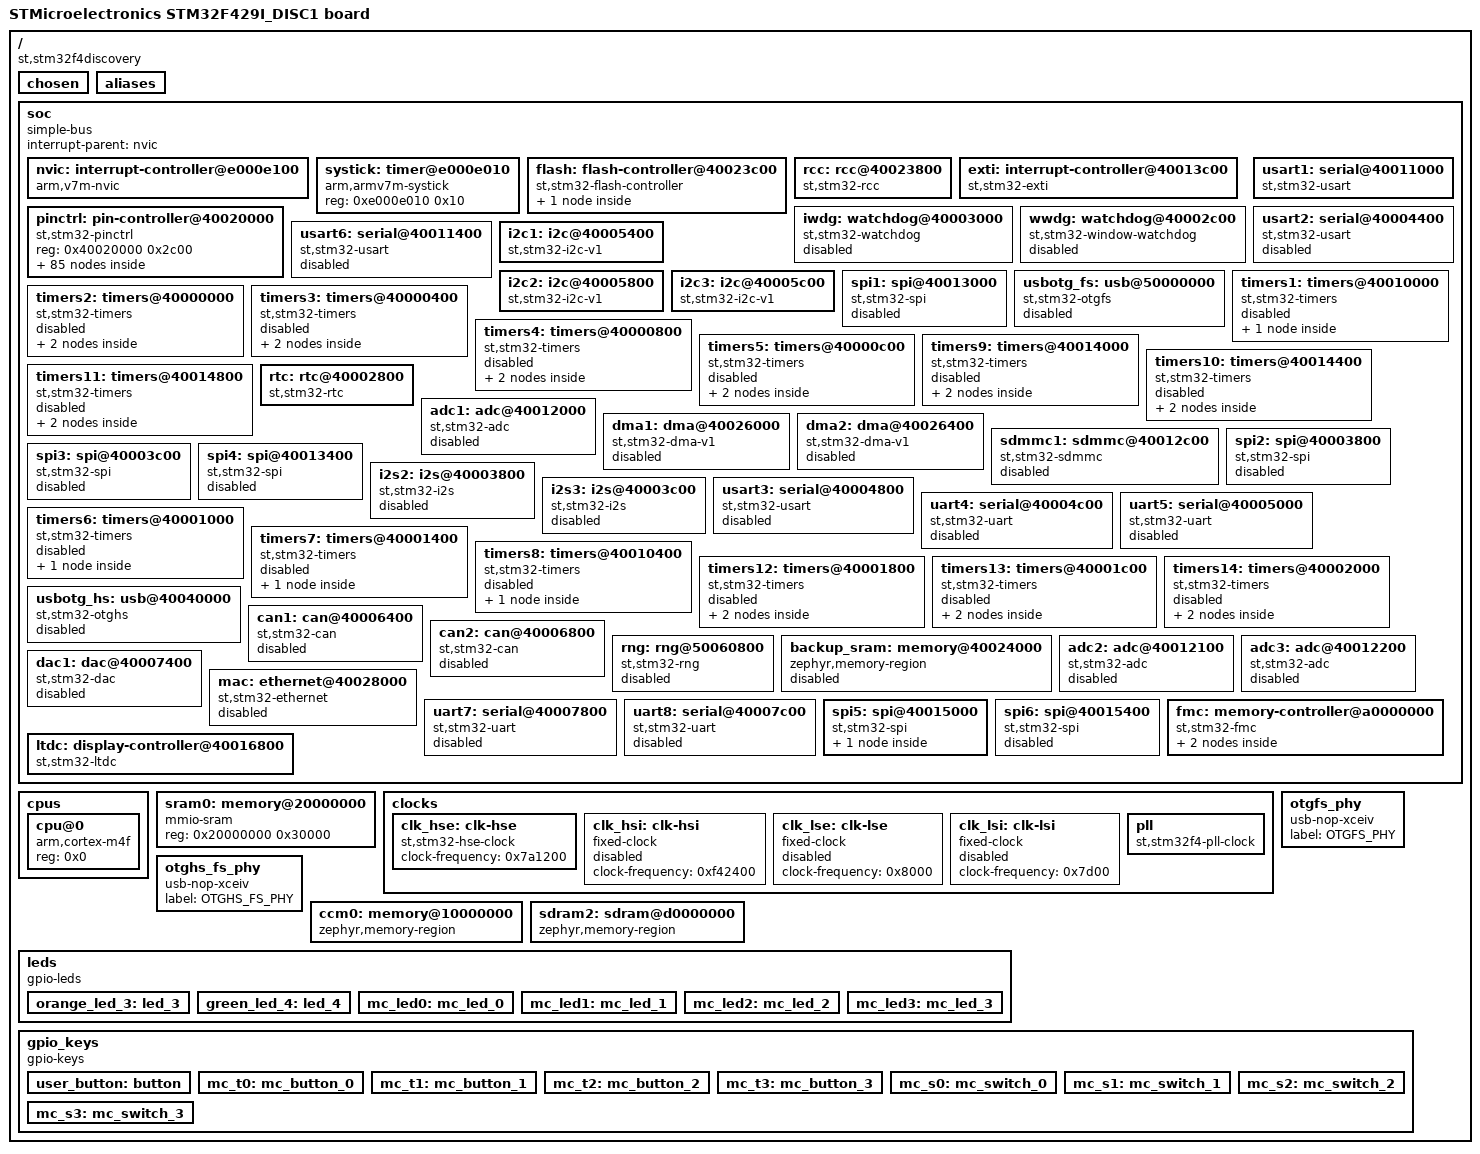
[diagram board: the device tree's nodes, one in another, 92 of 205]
/dts-v1/;

/ {
	#address-cells = < 0x1 >;
	#size-cells = < 0x1 >;
	model = "STMicroelectronics STM32F429I_DISC1 board";
	compatible = "st,stm32f4discovery";
	chosen {
		zephyr,flash-controller = &flash;
		zephyr,entropy = &rng;
		zephyr,console = &usart1;
		zephyr,shell-uart = &usart1;
		zephyr,sram = &sram0;
		zephyr,flash = &flash0;
		zephyr,ccm = &ccm0;
		zephyr,display = &ili9341;
		zephyr,tracing-uart = &usart1;
	};
	aliases {
		led0 = &green_led_4;
		sw0 = &user_button;
	};
	soc {
		#address-cells = < 0x1 >;
		#size-cells = < 0x1 >;
		compatible = "simple-bus";
		interrupt-parent = < &nvic >;
		ranges;
		nvic: interrupt-controller@e000e100 {
			#address-cells = < 0x1 >;
			compatible = "arm,v7m-nvic";
			reg = < 0xe000e100 0xc00 >;
			interrupt-controller;
			#interrupt-cells = < 0x2 >;
			arm,num-irq-priority-bits = < 0x4 >;
			phandle = < 0x1 >;
		};
		systick: timer@e000e010 {
			compatible = "arm,armv7m-systick";
			reg = < 0xe000e010 0x10 >;
		};
		flash: flash-controller@40023c00 {
			compatible = "st,stm32-flash-controller", "st,stm32f4-flash-controller";
			label = "FLASH_CTRL";
			reg = < 0x40023c00 0x400 >;
			interrupts = < 0x4 0x0 >;
			#address-cells = < 0x1 >;
			#size-cells = < 0x1 >;
			flash0: flash@8000000 {
				compatible = "st,stm32-nv-flash", "soc-nv-flash";
				label = "FLASH_STM32";
				write-block-size = < 0x1 >;
				max-erase-time = < 0xfa0 >;
				reg = < 0x8000000 0x200000 >;
			};
		};
		rcc: rcc@40023800 {
			compatible = "st,stm32-rcc";
			#clock-cells = < 0x2 >;
			reg = < 0x40023800 0x400 >;
			clocks = < &pll >;
			clock-frequency = < 0xa037a00 >;
			ahb-prescaler = < 0x1 >;
			apb1-prescaler = < 0x4 >;
			apb2-prescaler = < 0x2 >;
			phandle = < 0x3 >;
		};
		exti: interrupt-controller@40013c00 {
			compatible = "st,stm32-exti";
			interrupt-controller;
			#interrupt-cells = < 0x1 >;
			reg = < 0x40013c00 0x400 >;
		};
		pinctrl: pin-controller@40020000 {
			compatible = "st,stm32-pinctrl";
			#address-cells = < 0x1 >;
			#size-cells = < 0x1 >;
			reg = < 0x40020000 0x2c00 >;
			gpioa: gpio@40020000 {
				compatible = "st,stm32-gpio";
				gpio-controller;
				#gpio-cells = < 0x2 >;
				reg = < 0x40020000 0x400 >;
				clocks = < &rcc 0x30 0x1 >;
				label = "GPIOA";
				phandle = < 0x57 >;
			};
			gpiob: gpio@40020400 {
				compatible = "st,stm32-gpio";
				gpio-controller;
				#gpio-cells = < 0x2 >;
				reg = < 0x40020400 0x400 >;
				clocks = < &rcc 0x30 0x2 >;
				label = "GPIOB";
			};
			gpioc: gpio@40020800 {
				compatible = "st,stm32-gpio";
				gpio-controller;
				#gpio-cells = < 0x2 >;
				reg = < 0x40020800 0x400 >;
				clocks = < &rcc 0x30 0x4 >;
				label = "GPIOC";
				phandle = < 0x13 >;
			};
			gpiod: gpio@40020c00 {
				compatible = "st,stm32-gpio";
				gpio-controller;
				#gpio-cells = < 0x2 >;
				reg = < 0x40020c00 0x400 >;
				clocks = < &rcc 0x30 0x8 >;
				label = "GPIOD";
				phandle = < 0x14 >;
			};
			gpioe: gpio@40021000 {
				compatible = "st,stm32-gpio";
				gpio-controller;
				#gpio-cells = < 0x2 >;
				reg = < 0x40021000 0x400 >;
				clocks = < &rcc 0x30 0x10 >;
				label = "GPIOE";
				phandle = < 0x56 >;
			};
			gpiof: gpio@40021400 {
				compatible = "st,stm32-gpio";
				gpio-controller;
				#gpio-cells = < 0x2 >;
				reg = < 0x40021400 0x400 >;
				clocks = < &rcc 0x30 0x20 >;
				label = "GPIOF";
				phandle = < 0x58 >;
			};
			gpiog: gpio@40021800 {
				compatible = "st,stm32-gpio";
				gpio-controller;
				#gpio-cells = < 0x2 >;
				reg = < 0x40021800 0x400 >;
				clocks = < &rcc 0x30 0x40 >;
				label = "GPIOG";
				phandle = < 0x55 >;
			};
			gpioh: gpio@40021c00 {
				compatible = "st,stm32-gpio";
				gpio-controller;
				#gpio-cells = < 0x2 >;
				reg = < 0x40021c00 0x400 >;
				clocks = < &rcc 0x30 0x80 >;
				label = "GPIOH";
			};
			gpioi: gpio@40022000 {
				compatible = "st,stm32-gpio";
				gpio-controller;
				#gpio-cells = < 0x2 >;
				reg = < 0x40022000 0x400 >;
				clocks = < &rcc 0x30 0x100 >;
				label = "GPIOI";
			};
			gpioj: gpio@40022400 {
				compatible = "st,stm32-gpio";
				gpio-controller;
				#gpio-cells = < 0x2 >;
				reg = < 0x40022400 0x400 >;
				clocks = < &rcc 0x30 0x200 >;
				label = "GPIOJ";
			};
			gpiok: gpio@40022800 {
				compatible = "st,stm32-gpio";
				gpio-controller;
				#gpio-cells = < 0x2 >;
				reg = < 0x40022800 0x400 >;
				clocks = < &rcc 0x30 0x400 >;
				label = "GPIOK";
			};
			fmc_sdcke1_pb5: fmc_sdcke1_pb5 {
				pinmux = < 0x2ac >;
				bias-pull-up;
				slew-rate = "very-high-speed";
				phandle = < 0x19 >;
			};
			fmc_sdne1_pb6: fmc_sdne1_pb6 {
				pinmux = < 0x2cc >;
				bias-pull-up;
				slew-rate = "very-high-speed";
				phandle = < 0x1a >;
			};
			fmc_sdnwe_pc0: fmc_sdnwe_pc0 {
				pinmux = < 0x40c >;
				bias-pull-up;
				slew-rate = "very-high-speed";
				phandle = < 0x18 >;
			};
			fmc_d2_pd0: fmc_d2_pd0 {
				pinmux = < 0x60c >;
				bias-pull-up;
				slew-rate = "very-high-speed";
				phandle = < 0x2f >;
			};
			fmc_d3_pd1: fmc_d3_pd1 {
				pinmux = < 0x62c >;
				bias-pull-up;
				slew-rate = "very-high-speed";
				phandle = < 0x30 >;
			};
			fmc_d13_pd8: fmc_d13_pd8 {
				pinmux = < 0x70c >;
				bias-pull-up;
				slew-rate = "very-high-speed";
				phandle = < 0x3a >;
			};
			fmc_d14_pd9: fmc_d14_pd9 {
				pinmux = < 0x72c >;
				bias-pull-up;
				slew-rate = "very-high-speed";
				phandle = < 0x3b >;
			};
			fmc_d15_pd10: fmc_d15_pd10 {
				pinmux = < 0x74c >;
				bias-pull-up;
				slew-rate = "very-high-speed";
				phandle = < 0x3c >;
			};
			fmc_d0_pd14: fmc_d0_pd14 {
				pinmux = < 0x7cc >;
				bias-pull-up;
				slew-rate = "very-high-speed";
				phandle = < 0x2d >;
			};
			fmc_d1_pd15: fmc_d1_pd15 {
				pinmux = < 0x7ec >;
				bias-pull-up;
				slew-rate = "very-high-speed";
				phandle = < 0x2e >;
			};
			fmc_nbl0_pe0: fmc_nbl0_pe0 {
				pinmux = < 0x80c >;
				bias-pull-up;
				slew-rate = "very-high-speed";
				phandle = < 0x15 >;
			};
			fmc_nbl1_pe1: fmc_nbl1_pe1 {
				pinmux = < 0x82c >;
				bias-pull-up;
				slew-rate = "very-high-speed";
				phandle = < 0x16 >;
			};
			fmc_d4_pe7: fmc_d4_pe7 {
				pinmux = < 0x8ec >;
				bias-pull-up;
				slew-rate = "very-high-speed";
				phandle = < 0x31 >;
			};
			fmc_d5_pe8: fmc_d5_pe8 {
				pinmux = < 0x90c >;
				bias-pull-up;
				slew-rate = "very-high-speed";
				phandle = < 0x32 >;
			};
			fmc_d6_pe9: fmc_d6_pe9 {
				pinmux = < 0x92c >;
				bias-pull-up;
				slew-rate = "very-high-speed";
				phandle = < 0x33 >;
			};
			fmc_d7_pe10: fmc_d7_pe10 {
				pinmux = < 0x94c >;
				bias-pull-up;
				slew-rate = "very-high-speed";
				phandle = < 0x34 >;
			};
			fmc_d8_pe11: fmc_d8_pe11 {
				pinmux = < 0x96c >;
				bias-pull-up;
				slew-rate = "very-high-speed";
				phandle = < 0x35 >;
			};
			fmc_d9_pe12: fmc_d9_pe12 {
				pinmux = < 0x98c >;
				bias-pull-up;
				slew-rate = "very-high-speed";
				phandle = < 0x36 >;
			};
			fmc_d10_pe13: fmc_d10_pe13 {
				pinmux = < 0x9ac >;
				bias-pull-up;
				slew-rate = "very-high-speed";
				phandle = < 0x37 >;
			};
			fmc_d11_pe14: fmc_d11_pe14 {
				pinmux = < 0x9cc >;
				bias-pull-up;
				slew-rate = "very-high-speed";
				phandle = < 0x38 >;
			};
			fmc_d12_pe15: fmc_d12_pe15 {
				pinmux = < 0x9ec >;
				bias-pull-up;
				slew-rate = "very-high-speed";
				phandle = < 0x39 >;
			};
			fmc_a0_pf0: fmc_a0_pf0 {
				pinmux = < 0xa0c >;
				bias-pull-up;
				slew-rate = "very-high-speed";
				phandle = < 0x1d >;
			};
			fmc_a1_pf1: fmc_a1_pf1 {
				pinmux = < 0xa2c >;
				bias-pull-up;
				slew-rate = "very-high-speed";
				phandle = < 0x1e >;
			};
			fmc_a2_pf2: fmc_a2_pf2 {
				pinmux = < 0xa4c >;
				bias-pull-up;
				slew-rate = "very-high-speed";
				phandle = < 0x1f >;
			};
			fmc_a3_pf3: fmc_a3_pf3 {
				pinmux = < 0xa6c >;
				bias-pull-up;
				slew-rate = "very-high-speed";
				phandle = < 0x20 >;
			};
			fmc_a4_pf4: fmc_a4_pf4 {
				pinmux = < 0xa8c >;
				bias-pull-up;
				slew-rate = "very-high-speed";
				phandle = < 0x21 >;
			};
			fmc_a5_pf5: fmc_a5_pf5 {
				pinmux = < 0xaac >;
				bias-pull-up;
				slew-rate = "very-high-speed";
				phandle = < 0x22 >;
			};
			fmc_sdnras_pf11: fmc_sdnras_pf11 {
				pinmux = < 0xb6c >;
				bias-pull-up;
				slew-rate = "very-high-speed";
				phandle = < 0x1b >;
			};
			fmc_a6_pf12: fmc_a6_pf12 {
				pinmux = < 0xb8c >;
				bias-pull-up;
				slew-rate = "very-high-speed";
				phandle = < 0x23 >;
			};
			fmc_a7_pf13: fmc_a7_pf13 {
				pinmux = < 0xbac >;
				bias-pull-up;
				slew-rate = "very-high-speed";
				phandle = < 0x24 >;
			};
			fmc_a8_pf14: fmc_a8_pf14 {
				pinmux = < 0xbcc >;
				bias-pull-up;
				slew-rate = "very-high-speed";
				phandle = < 0x25 >;
			};
			fmc_a9_pf15: fmc_a9_pf15 {
				pinmux = < 0xbec >;
				bias-pull-up;
				slew-rate = "very-high-speed";
				phandle = < 0x26 >;
			};
			fmc_a10_pg0: fmc_a10_pg0 {
				pinmux = < 0xc0c >;
				bias-pull-up;
				slew-rate = "very-high-speed";
				phandle = < 0x27 >;
			};
			fmc_a11_pg1: fmc_a11_pg1 {
				pinmux = < 0xc2c >;
				bias-pull-up;
				slew-rate = "very-high-speed";
				phandle = < 0x28 >;
			};
			fmc_a12_pg2: fmc_a12_pg2 {
				pinmux = < 0xc4c >;
				bias-pull-up;
				slew-rate = "very-high-speed";
				phandle = < 0x29 >;
			};
			fmc_a13_pg3: fmc_a13_pg3 {
				pinmux = < 0xc6c >;
				bias-pull-up;
				slew-rate = "very-high-speed";
				phandle = < 0x2a >;
			};
			fmc_a14_pg4: fmc_a14_pg4 {
				pinmux = < 0xc8c >;
				bias-pull-up;
				slew-rate = "very-high-speed";
				phandle = < 0x2b >;
			};
			fmc_a15_pg5: fmc_a15_pg5 {
				pinmux = < 0xcac >;
				bias-pull-up;
				slew-rate = "very-high-speed";
				phandle = < 0x2c >;
			};
			fmc_sdclk_pg8: fmc_sdclk_pg8 {
				pinmux = < 0xd0c >;
				bias-pull-up;
				slew-rate = "very-high-speed";
				phandle = < 0x17 >;
			};
			fmc_sdncas_pg15: fmc_sdncas_pg15 {
				pinmux = < 0xdec >;
				bias-pull-up;
				slew-rate = "very-high-speed";
				phandle = < 0x1c >;
			};
			i2c1_scl_pb8: i2c1_scl_pb8 {
				pinmux = < 0x304 >;
				bias-pull-up;
				drive-open-drain;
				phandle = < 0x6 >;
			};
			i2c2_scl_pb10: i2c2_scl_pb10 {
				pinmux = < 0x344 >;
				bias-pull-up;
				drive-open-drain;
				phandle = < 0x8 >;
			};
			i2c3_scl_pa8: i2c3_scl_pa8 {
				pinmux = < 0x104 >;
				bias-pull-up;
				drive-open-drain;
				phandle = < 0xa >;
			};
			i2c1_sda_pb9: i2c1_sda_pb9 {
				pinmux = < 0x324 >;
				bias-pull-up;
				drive-open-drain;
				phandle = < 0x7 >;
			};
			i2c2_sda_pb11: i2c2_sda_pb11 {
				pinmux = < 0x364 >;
				bias-pull-up;
				drive-open-drain;
				phandle = < 0x9 >;
			};
			i2c3_sda_pc9: i2c3_sda_pc9 {
				pinmux = < 0x524 >;
				bias-pull-up;
				drive-open-drain;
				phandle = < 0xb >;
			};
			ltdc_b5_pa3: ltdc_b5_pa3 {
				pinmux = < 0x6e >;
				phandle = < 0x4c >;
			};
			ltdc_vsync_pa4: ltdc_vsync_pa4 {
				pinmux = < 0x8e >;
				phandle = < 0x52 >;
			};
			ltdc_g2_pa6: ltdc_g2_pa6 {
				pinmux = < 0xce >;
				phandle = < 0x43 >;
			};
			ltdc_r4_pa11: ltdc_r4_pa11 {
				pinmux = < 0x16e >;
				phandle = < 0x3f >;
			};
			ltdc_r5_pa12: ltdc_r5_pa12 {
				pinmux = < 0x18e >;
				phandle = < 0x40 >;
			};
			ltdc_r3_pb0: ltdc_r3_pb0 {
				pinmux = < 0x209 >;
				phandle = < 0x3e >;
			};
			ltdc_r6_pb1: ltdc_r6_pb1 {
				pinmux = < 0x229 >;
				phandle = < 0x41 >;
			};
			ltdc_b6_pb8: ltdc_b6_pb8 {
				pinmux = < 0x30e >;
				phandle = < 0x4d >;
			};
			ltdc_b7_pb9: ltdc_b7_pb9 {
				pinmux = < 0x32e >;
				phandle = < 0x4e >;
			};
			ltdc_g4_pb10: ltdc_g4_pb10 {
				pinmux = < 0x34e >;
				phandle = < 0x45 >;
			};
			ltdc_g5_pb11: ltdc_g5_pb11 {
				pinmux = < 0x36e >;
				phandle = < 0x46 >;
			};
			ltdc_hsync_pc6: ltdc_hsync_pc6 {
				pinmux = < 0x4ce >;
				phandle = < 0x51 >;
			};
			ltdc_g6_pc7: ltdc_g6_pc7 {
				pinmux = < 0x4ee >;
				phandle = < 0x47 >;
			};
			ltdc_r2_pc10: ltdc_r2_pc10 {
				pinmux = < 0x54e >;
				phandle = < 0x3d >;
			};
			ltdc_g7_pd3: ltdc_g7_pd3 {
				pinmux = < 0x66e >;
				phandle = < 0x48 >;
			};
			ltdc_b2_pd6: ltdc_b2_pd6 {
				pinmux = < 0x6ce >;
				phandle = < 0x49 >;
			};
			ltdc_de_pf10: ltdc_de_pf10 {
				pinmux = < 0xb4e >;
				phandle = < 0x4f >;
			};
			ltdc_r7_pg6: ltdc_r7_pg6 {
				pinmux = < 0xcce >;
				phandle = < 0x42 >;
			};
			ltdc_clk_pg7: ltdc_clk_pg7 {
				pinmux = < 0xcee >;
				phandle = < 0x50 >;
			};
			ltdc_g3_pg10: ltdc_g3_pg10 {
				pinmux = < 0xd49 >;
				phandle = < 0x44 >;
			};
			ltdc_b3_pg11: ltdc_b3_pg11 {
				pinmux = < 0xd6e >;
				phandle = < 0x4a >;
			};
			ltdc_b4_pg12: ltdc_b4_pg12 {
				pinmux = < 0xd89 >;
				phandle = < 0x4b >;
			};
			spi5_miso_pf8: spi5_miso_pf8 {
				pinmux = < 0xb05 >;
				bias-pull-down;
				phandle = < 0x11 >;
			};
			spi5_mosi_pf9: spi5_mosi_pf9 {
				pinmux = < 0xb25 >;
				bias-pull-down;
				phandle = < 0x12 >;
			};
			spi5_nss_pf6: spi5_nss_pf6 {
				pinmux = < 0xac5 >;
				bias-pull-up;
				phandle = < 0xf >;
			};
			spi5_sck_pf7: spi5_sck_pf7 {
				pinmux = < 0xae5 >;
				bias-pull-down;
				slew-rate = "very-high-speed";
				phandle = < 0x10 >;
			};
			usart1_rx_pa10: usart1_rx_pa10 {
				pinmux = < 0x147 >;
				phandle = < 0x5 >;
			};
			usart1_tx_pa9: usart1_tx_pa9 {
				pinmux = < 0x127 >;
				bias-pull-up;
				phandle = < 0x4 >;
			};
		};
		iwdg: watchdog@40003000 {
			compatible = "st,stm32-watchdog";
			reg = < 0x40003000 0x400 >;
			label = "IWDG";
			status = "disabled";
		};
		wwdg: watchdog@40002c00 {
			compatible = "st,stm32-window-watchdog";
			reg = < 0x40002c00 0x400 >;
			clocks = < &rcc 0x40 0x800 >;
			label = "WWDG";
			interrupts = < 0x0 0x7 >;
			status = "disabled";
		};
		usart1: serial@40011000 {
			compatible = "st,stm32-usart", "st,stm32-uart";
			reg = < 0x40011000 0x400 >;
			clocks = < &rcc 0x44 0x10 >;
			interrupts = < 0x25 0x0 >;
			status = "okay";
			label = "UART_1";
			pinctrl-0 = < &usart1_tx_pa9 &usart1_rx_pa10 >;
			pinctrl-names = "default";
			current-speed = < 0x1c200 >;
		};
		usart2: serial@40004400 {
			compatible = "st,stm32-usart", "st,stm32-uart";
			reg = < 0x40004400 0x400 >;
			clocks = < &rcc 0x40 0x20000 >;
			interrupts = < 0x26 0x0 >;
			status = "disabled";
			label = "UART_2";
		};
		usart6: serial@40011400 {
			compatible = "st,stm32-usart", "st,stm32-uart";
			reg = < 0x40011400 0x400 >;
			clocks = < &rcc 0x44 0x20 >;
			interrupts = < 0x47 0x0 >;
			status = "disabled";
			label = "UART_6";
		};
		i2c1: i2c@40005400 {
			compatible = "st,stm32-i2c-v1";
			clock-frequency = < 0x61a80 >;
			#address-cells = < 0x1 >;
			#size-cells = < 0x0 >;
			reg = < 0x40005400 0x400 >;
			clocks = < &rcc 0x40 0x200000 >;
			interrupts = < 0x1f 0x0 >, < 0x20 0x0 >;
			interrupt-names = "event", "error";
			status = "okay";
			label = "I2C_1";
			pinctrl-0 = < &i2c1_scl_pb8 &i2c1_sda_pb9 >;
			pinctrl-names = "default";
		};
		i2c2: i2c@40005800 {
			compatible = "st,stm32-i2c-v1";
			clock-frequency = < 0x61a80 >;
			#address-cells = < 0x1 >;
			#size-cells = < 0x0 >;
			reg = < 0x40005800 0x400 >;
			clocks = < &rcc 0x40 0x400000 >;
			interrupts = < 0x21 0x0 >, < 0x22 0x0 >;
			interrupt-names = "event", "error";
			status = "okay";
			label = "I2C_2";
			pinctrl-0 = < &i2c2_scl_pb10 &i2c2_sda_pb11 >;
			pinctrl-names = "default";
		};
		i2c3: i2c@40005c00 {
			compatible = "st,stm32-i2c-v1";
			clock-frequency = < 0x61a80 >;
			#address-cells = < 0x1 >;
			#size-cells = < 0x0 >;
			reg = < 0x40005c00 0x400 >;
			clocks = < &rcc 0x40 0x800000 >;
			interrupts = < 0x48 0x0 >, < 0x49 0x0 >;
			interrupt-names = "event", "error";
			status = "okay";
			label = "I2C_3";
			pinctrl-0 = < &i2c3_scl_pa8 &i2c3_sda_pc9 >;
			pinctrl-names = "default";
		};
		spi1: spi@40013000 {
			compatible = "st,stm32-spi";
			#address-cells = < 0x1 >;
			#size-cells = < 0x0 >;
			reg = < 0x40013000 0x400 >;
			clocks = < &rcc 0x44 0x1000 >;
			interrupts = < 0x23 0x5 >;
			status = "disabled";
			label = "SPI_1";
		};
		usbotg_fs: usb@50000000 {
			compatible = "st,stm32-otgfs";
			reg = < 0x50000000 0x40000 >;
			interrupts = < 0x43 0x0 >;
			interrupt-names = "otgfs";
			num-bidir-endpoints = < 0x4 >;
			ram-size = < 0x500 >;
			maximum-speed = "full-speed";
			phys = < &otgfs_phy >;
			clocks = < &rcc 0x34 0x80 >;
			status = "disabled";
			label = "OTGFS";
		};
		timers1: timers@40010000 {
			compatible = "st,stm32-timers";
			reg = < 0x40010000 0x400 >;
			clocks = < &rcc 0x44 0x1 >;
			interrupts = < 0x18 0x0 >, < 0x19 0x0 >, < 0x1a 0x0 >, < 0x1b 0x0 >;
			interrupt-names = "brk", "up", "trgcom", "cc";
			st,prescaler = < 0x0 >;
			status = "disabled";
			label = "TIMERS_1";
			pwm {
				compatible = "st,stm32-pwm";
				status = "disabled";
				label = "PWM_1";
				#pwm-cells = < 0x3 >;
			};
		};
		timers2: timers@40000000 {
			compatible = "st,stm32-timers";
			reg = < 0x40000000 0x400 >;
			clocks = < &rcc 0x40 0x1 >;
			interrupts = < 0x1c 0x0 >;
			interrupt-names = "global";
			st,prescaler = < 0x0 >;
			status = "disabled";
			label = "TIMERS_2";
			pwm {
				compatible = "st,stm32-pwm";
				status = "disabled";
				label = "PWM_2";
				#pwm-cells = < 0x3 >;
			};
			counter {
				compatible = "st,stm32-counter";
				status = "disabled";
				label = "COUNTER_2";
			};
		};
		timers3: timers@40000400 {
			compatible = "st,stm32-timers";
			reg = < 0x40000400 0x400 >;
			clocks = < &rcc 0x40 0x2 >;
			interrupts = < 0x1d 0x0 >;
			interrupt-names = "global";
			st,prescaler = < 0x0 >;
			status = "disabled";
			label = "TIMERS_3";
			pwm {
				compatible = "st,stm32-pwm";
				status = "disabled";
				label = "PWM_3";
				#pwm-cells = < 0x3 >;
			};
			counter {
				compatible = "st,stm32-counter";
				status = "disabled";
				label = "COUNTER_3";
			};
		};
		timers4: timers@40000800 {
			compatible = "st,stm32-timers";
			reg = < 0x40000800 0x400 >;
			clocks = < &rcc 0x40 0x4 >;
			interrupts = < 0x1e 0x0 >;
			interrupt-names = "global";
			st,prescaler = < 0x0 >;
			status = "disabled";
			label = "TIMERS_4";
			pwm {
				compatible = "st,stm32-pwm";
				status = "disabled";
				label = "PWM_4";
				#pwm-cells = < 0x3 >;
			};
			counter {
				compatible = "st,stm32-counter";
				status = "disabled";
				label = "COUNTER_4";
			};
		};
		timers5: timers@40000c00 {
			compatible = "st,stm32-timers";
			reg = < 0x40000c00 0x400 >;
			clocks = < &rcc 0x40 0x8 >;
			interrupts = < 0x32 0x0 >;
			interrupt-names = "global";
			st,prescaler = < 0x0 >;
			status = "disabled";
			label = "TIMERS_5";
			pwm {
				compatible = "st,stm32-pwm";
				status = "disabled";
				label = "PWM_5";
				#pwm-cells = < 0x3 >;
			};
			counter {
				compatible = "st,stm32-counter";
				status = "disabled";
				label = "COUNTER_5";
			};
		};
		timers9: timers@40014000 {
			compatible = "st,stm32-timers";
			reg = < 0x40014000 0x400 >;
			clocks = < &rcc 0x44 0x10000 >;
			interrupts = < 0x18 0x0 >;
			interrupt-names = "global";
			st,prescaler = < 0x0 >;
			status = "disabled";
			label = "TIMERS_9";
			pwm {
				compatible = "st,stm32-pwm";
				status = "disabled";
				label = "PWM_9";
				#pwm-cells = < 0x3 >;
			};
			counter {
				compatible = "st,stm32-counter";
				status = "disabled";
				label = "COUNTER_9";
			};
		};
		timers10: timers@40014400 {
			compatible = "st,stm32-timers";
			reg = < 0x40014400 0x400 >;
			clocks = < &rcc 0x44 0x20000 >;
			interrupts = < 0x19 0x0 >;
			interrupt-names = "global";
			st,prescaler = < 0x0 >;
			status = "disabled";
			label = "TIMERS_10";
			pwm {
				compatible = "st,stm32-pwm";
				status = "disabled";
				label = "PWM_10";
				#pwm-cells = < 0x3 >;
			};
			counter {
				compatible = "st,stm32-counter";
				status = "disabled";
				label = "COUNTER_10";
			};
		};
		timers11: timers@40014800 {
			compatible = "st,stm32-timers";
			reg = < 0x40014800 0x400 >;
			clocks = < &rcc 0x44 0x40000 >;
			interrupts = < 0x1a 0x0 >;
			interrupt-names = "global";
			st,prescaler = < 0x0 >;
			status = "disabled";
			label = "TIMERS_11";
			pwm {
				compatible = "st,stm32-pwm";
				status = "disabled";
				label = "PWM_11";
				#pwm-cells = < 0x3 >;
			};
			counter {
				compatible = "st,stm32-counter";
				status = "disabled";
				label = "COUNTER_11";
			};
		};
		rtc: rtc@40002800 {
			compatible = "st,stm32-rtc";
			reg = < 0x40002800 0x400 >;
			interrupts = < 0x29 0x0 >;
			clocks = < &rcc 0x40 0x10000000 >;
			prescaler = < 0x8000 >;
			status = "okay";
			label = "RTC_0";
		};
		adc1: adc@40012000 {
			compatible = "st,stm32-adc";
			reg = < 0x40012000 0x400 >;
			clocks = < &rcc 0x44 0x100 >;
			interrupts = < 0x12 0x0 >;
			status = "disabled";
			label = "ADC_1";
			#io-channel-cells = < 0x1 >;
			has-temp-channel;
			has-vref-channel;
		};
		dma1: dma@40026000 {
			compatible = "st,stm32-dma-v1";
			#dma-cells = < 0x4 >;
			reg = < 0x40026000 0x400 >;
			interrupts = < 0xb 0x0 0xc 0x0 0xd 0x0 0xe 0x0 0xf 0x0 0x10 0x0 0x11 0x0 0x2f 0x0 >;
			clocks = < &rcc 0x30 0x200000 >;
			status = "disabled";
			label = "DMA_1";
			phandle = < 0xd >;
		};
		dma2: dma@40026400 {
			compatible = "st,stm32-dma-v1";
			#dma-cells = < 0x4 >;
			reg = < 0x40026400 0x400 >;
			interrupts = < 0x38 0x0 0x39 0x0 0x3a 0x0 0x3b 0x0 0x3c 0x0 0x44 0x0 0x45 0x0 0x46 0x0 >;
			clocks = < &rcc 0x30 0x400000 >;
			st,mem2mem;
			status = "disabled";
			label = "DMA_2";
		};
		sdmmc1: sdmmc@40012c00 {
			compatible = "st,stm32-sdmmc";
			reg = < 0x40012c00 0x400 >;
			clocks = < &rcc 0x44 0x800 >;
			interrupts = < 0x31 0x0 >;
			status = "disabled";
			label = "SDMMC_1";
		};
		spi2: spi@40003800 {
			compatible = "st,stm32-spi";
			#address-cells = < 0x1 >;
			#size-cells = < 0x0 >;
			reg = < 0x40003800 0x400 >;
			clocks = < &rcc 0x40 0x4000 >;
			interrupts = < 0x24 0x5 >;
			status = "disabled";
			label = "SPI_2";
		};
		spi3: spi@40003c00 {
			compatible = "st,stm32-spi";
			#address-cells = < 0x1 >;
			#size-cells = < 0x0 >;
			reg = < 0x40003c00 0x400 >;
			clocks = < &rcc 0x40 0x8000 >;
			interrupts = < 0x33 0x5 >;
			status = "disabled";
			label = "SPI_3";
		};
		spi4: spi@40013400 {
			compatible = "st,stm32-spi";
			#address-cells = < 0x1 >;
			#size-cells = < 0x0 >;
			reg = < 0x40013400 0x400 >;
			clocks = < &rcc 0x44 0x2000 >;
			interrupts = < 0x54 0x5 >;
			status = "disabled";
			label = "SPI_4";
		};
		i2s2: i2s@40003800 {
			compatible = "st,stm32-i2s";
			#address-cells = < 0x1 >;
			#size-cells = < 0x0 >;
			reg = < 0x40003800 0x400 >;
			clocks = < &rcc 0x40 0x4000 >;
			interrupts = < 0x24 0x5 >;
			dmas = < &dma1 0x4 0x0 0x400 0x3 &dma1 0x3 0x0 0x400 0x3 >;
			dma-names = "tx", "rx";
			status = "disabled";
			label = "I2S_2";
		};
		i2s3: i2s@40003c00 {
			compatible = "st,stm32-i2s";
			#address-cells = < 0x1 >;
			#size-cells = < 0x0 >;
			reg = < 0x40003c00 0x400 >;
			clocks = < &rcc 0x40 0x8000 >;
			interrupts = < 0x33 0x5 >;
			dmas = < &dma1 0x5 0x0 0x400 0x3 &dma1 0x0 0x0 0x400 0x3 >;
			dma-names = "tx", "rx";
			status = "disabled";
			label = "I2S_3";
		};
		usart3: serial@40004800 {
			compatible = "st,stm32-usart", "st,stm32-uart";
			reg = < 0x40004800 0x400 >;
			clocks = < &rcc 0x40 0x40000 >;
			interrupts = < 0x27 0x0 >;
			status = "disabled";
			label = "UART_3";
		};
		uart4: serial@40004c00 {
			compatible = "st,stm32-uart";
			reg = < 0x40004c00 0x400 >;
			clocks = < &rcc 0x40 0x80000 >;
			interrupts = < 0x34 0x0 >;
			status = "disabled";
			label = "UART_4";
		};
		uart5: serial@40005000 {
			compatible = "st,stm32-uart";
			reg = < 0x40005000 0x400 >;
			clocks = < &rcc 0x40 0x100000 >;
			interrupts = < 0x35 0x0 >;
			status = "disabled";
			label = "UART_5";
		};
		timers6: timers@40001000 {
			compatible = "st,stm32-timers";
			reg = < 0x40001000 0x400 >;
			clocks = < &rcc 0x40 0x10 >;
			interrupts = < 0x36 0x0 >;
			interrupt-names = "global";
			st,prescaler = < 0x0 >;
			status = "disabled";
			label = "TIMERS_6";
			counter {
				compatible = "st,stm32-counter";
				status = "disabled";
				label = "COUNTER_6";
			};
		};
		timers7: timers@40001400 {
			compatible = "st,stm32-timers";
			reg = < 0x40001400 0x400 >;
			clocks = < &rcc 0x40 0x20 >;
			interrupts = < 0x37 0x0 >;
			interrupt-names = "global";
			st,prescaler = < 0x0 >;
			status = "disabled";
			label = "TIMERS_7";
			counter {
				compatible = "st,stm32-counter";
				status = "disabled";
				label = "COUNTER_7";
			};
		};
		timers8: timers@40010400 {
			compatible = "st,stm32-timers";
			reg = < 0x40010400 0x400 >;
			clocks = < &rcc 0x44 0x2 >;
			interrupts = < 0x2b 0x0 >, < 0x2c 0x0 >, < 0x2d 0x0 >, < 0x2e 0x0 >;
			interrupt-names = "brk", "up", "trgcom", "cc";
			st,prescaler = < 0x0 >;
			status = "disabled";
			label = "TIMERS_8";
			pwm {
				compatible = "st,stm32-pwm";
				status = "disabled";
				label = "PWM_8";
				#pwm-cells = < 0x3 >;
			};
		};
		timers12: timers@40001800 {
			compatible = "st,stm32-timers";
			reg = < 0x40001800 0x400 >;
			clocks = < &rcc 0x40 0x40 >;
			interrupts = < 0x2b 0x0 >;
			interrupt-names = "global";
			st,prescaler = < 0x0 >;
			status = "disabled";
			label = "TIMERS_12";
			pwm {
				compatible = "st,stm32-pwm";
				status = "disabled";
				label = "PWM_12";
				#pwm-cells = < 0x3 >;
			};
			counter {
				compatible = "st,stm32-counter";
				status = "disabled";
				label = "COUNTER_12";
			};
		};
		timers13: timers@40001c00 {
			compatible = "st,stm32-timers";
			reg = < 0x40001c00 0x400 >;
			clocks = < &rcc 0x40 0x80 >;
			interrupts = < 0x2c 0x0 >;
			interrupt-names = "global";
			st,prescaler = < 0x0 >;
			status = "disabled";
			label = "TIMERS_13";
			pwm {
				compatible = "st,stm32-pwm";
				status = "disabled";
				label = "PWM_13";
				#pwm-cells = < 0x3 >;
			};
			counter {
				compatible = "st,stm32-counter";
				status = "disabled";
				label = "COUNTER_13";
			};
		};
		timers14: timers@40002000 {
			compatible = "st,stm32-timers";
			reg = < 0x40002000 0x400 >;
			clocks = < &rcc 0x40 0x100 >;
			interrupts = < 0x2d 0x0 >;
			interrupt-names = "global";
			st,prescaler = < 0x0 >;
			status = "disabled";
			label = "TIMERS_14";
			pwm {
				compatible = "st,stm32-pwm";
				status = "disabled";
				label = "PWM_14";
				#pwm-cells = < 0x3 >;
			};
			counter {
				compatible = "st,stm32-counter";
				status = "disabled";
				label = "COUNTER_14";
			};
		};
		usbotg_hs: usb@40040000 {
			compatible = "st,stm32-otghs";
			reg = < 0x40040000 0x40000 >;
			interrupts = < 0x4d 0x0 >, < 0x4a 0x0 >, < 0x4b 0x0 >;
			interrupt-names = "otghs", "ep1_out", "ep1_in";
			num-bidir-endpoints = < 0x6 >;
			ram-size = < 0x1000 >;
			maximum-speed = "full-speed";
			phys = < &otghs_fs_phy >;
			clocks = < &rcc 0x30 0x20000000 >;
			status = "disabled";
			label = "OTGHS";
		};
		can1: can@40006400 {
			compatible = "st,stm32-can";
			reg = < 0x40006400 0x400 >;
			interrupts = < 0x13 0x0 >, < 0x14 0x0 >, < 0x15 0x0 >, < 0x16 0x0 >;
			interrupt-names = "TX", "RX0", "RX1", "SCE";
			clocks = < &rcc 0x40 0x2000000 >;
			status = "disabled";
			label = "CAN_1";
			sjw = < 0x1 >;
			sample-point = < 0x36b >;
		};
		can2: can@40006800 {
			compatible = "st,stm32-can";
			reg = < 0x40006800 0x400 >;
			interrupts = < 0x3f 0x0 >, < 0x40 0x0 >, < 0x41 0x0 >, < 0x42 0x0 >;
			interrupt-names = "TX", "RX0", "RX1", "SCE";
			clocks = < &rcc 0x40 0x6000000 >;
			master-can-reg = < 0x40006400 >;
			status = "disabled";
			label = "CAN_2";
			sjw = < 0x1 >;
			sample-point = < 0x36b >;
		};
		rng: rng@50060800 {
			compatible = "st,stm32-rng";
			reg = < 0x50060800 0x400 >;
			interrupts = < 0x50 0x0 >;
			clocks = < &rcc 0x34 0x40 >;
			status = "disabled";
			label = "RNG";
		};
		backup_sram: memory@40024000 {
			compatible = "zephyr,memory-region", "st,stm32-backup-sram";
			reg = < 0x40024000 0x1000 >;
			clocks = < &rcc 0x30 0x40000 >;
			label = "BACKUP_SRAM";
			zephyr,memory-region = "BACKUP_SRAM";
			status = "disabled";
		};
		adc2: adc@40012100 {
			compatible = "st,stm32-adc";
			reg = < 0x40012100 0x50 >;
			clocks = < &rcc 0x44 0x200 >;
			interrupts = < 0x12 0x0 >;
			status = "disabled";
			label = "ADC_2";
			#io-channel-cells = < 0x1 >;
		};
		adc3: adc@40012200 {
			compatible = "st,stm32-adc";
			reg = < 0x40012200 0x50 >;
			clocks = < &rcc 0x44 0x400 >;
			interrupts = < 0x12 0x0 >;
			status = "disabled";
			label = "ADC_3";
			#io-channel-cells = < 0x1 >;
		};
		dac1: dac@40007400 {
			compatible = "st,stm32-dac";
			reg = < 0x40007400 0x400 >;
			clocks = < &rcc 0x40 0x20000000 >;
			status = "disabled";
			label = "DAC_1";
			#io-channel-cells = < 0x1 >;
		};
		mac: ethernet@40028000 {
			compatible = "st,stm32-ethernet";
			reg = < 0x40028000 0x8000 >;
			label = "ETH_0";
			interrupts = < 0x3d 0x0 >;
			clock-names = "stmmaceth", "mac-clk-tx", "mac-clk-rx", "mac-clk-ptp";
			clocks = < &rcc 0x30 0x2000000 >, < &rcc 0x30 0x4000000 >, < &rcc 0x30 0x8000000 >, < &rcc 0x30 0x10000000 >;
			status = "disabled";
		};
		uart7: serial@40007800 {
			compatible = "st,stm32-uart";
			reg = < 0x40007800 0x400 >;
			clocks = < &rcc 0x40 0x40000000 >;
			interrupts = < 0x52 0x0 >;
			status = "disabled";
			label = "UART_7";
		};
		uart8: serial@40007c00 {
			compatible = "st,stm32-uart";
			reg = < 0x40007c00 0x400 >;
			clocks = < &rcc 0x40 0x80000000 >;
			interrupts = < 0x53 0x0 >;
			status = "disabled";
			label = "UART_8";
		};
		spi5: spi@40015000 {
			compatible = "st,stm32-spi";
			#address-cells = < 0x1 >;
			#size-cells = < 0x0 >;
			reg = < 0x40015000 0x400 >;
			clocks = < &rcc 0x44 0x100000 >;
			interrupts = < 0x55 0x5 >;
			status = "okay";
			label = "SPI_5";
			pinctrl-0 = < &spi5_nss_pf6 &spi5_sck_pf7 &spi5_miso_pf8 &spi5_mosi_pf9 >;
			pinctrl-names = "default";
			cs-gpios = < &gpioc 0x2 0x1 >;
			ili9341: ili9341@0 {
				compatible = "ilitek,ili9341";
				label = "ILI9341";
				spi-max-frequency = < 0x55d4a8 >;
				reg = < 0x0 >;
				cmd-data-gpios = < &gpiod 0xd 0x1 >;
				width = < 0xf0 >;
				height = < 0x140 >;
				rotation = < 0x10e >;
				pixel-format = < 0x0 >;
				pwctrla = [ 39 2C 00 34 02 ];
				pwctrlb = [ 00 F9 F7 ];
				timctrla = [ 85 00 78 ];
				timctrlb = [ 00 00 ];
				pwseqctrl = [ 64 03 12 81 ];
				pumpratioctrl = [ 20 ];
				disctrl = [ 0A 82 27 ];
				vmctrl1 = [ 49 60 ];
				vmctrl2 = [ C0 ];
				enable3g = [ 02 ];
				ifctl = [ 01 00 00 ];
				ifmode = [ 64 ];
				gamset = [ 01 ];
				frmctr1 = [ 00 18 ];
				pwctrl1 = [ 20 ];
				pwctrl2 = [ 10 ];
				pgamctrl = [ 0F 29 24 0C 0E 09 4E 78 3C 09 13 05 17 11 00 ];
				ngamctrl = [ 00 16 1B 04 11 07 31 33 42 05 0C 0A 28 2F 0F ];
			};
		};
		spi6: spi@40015400 {
			compatible = "st,stm32-spi";
			#address-cells = < 0x1 >;
			#size-cells = < 0x0 >;
			reg = < 0x40015400 0x400 >;
			clocks = < &rcc 0x44 0x200000 >;
			interrupts = < 0x56 0x5 >;
			status = "disabled";
			label = "SPI_6";
		};
		fmc: memory-controller@a0000000 {
			compatible = "st,stm32-fmc";
			reg = < 0xa0000000 0x400 >;
			clocks = < &rcc 0x38 0x1 >;
			label = "STM32_FMC";
			status = "okay";
			pinctrl-0 = < &fmc_nbl0_pe0 &fmc_nbl1_pe1 &fmc_sdclk_pg8 &fmc_sdnwe_pc0 &fmc_sdcke1_pb5 &fmc_sdne1_pb6 &fmc_sdnras_pf11 &fmc_sdncas_pg15 &fmc_a0_pf0 &fmc_a1_pf1 &fmc_a2_pf2 &fmc_a3_pf3 &fmc_a4_pf4 &fmc_a5_pf5 &fmc_a6_pf12 &fmc_a7_pf13 &fmc_a8_pf14 &fmc_a9_pf15 &fmc_a10_pg0 &fmc_a11_pg1 &fmc_a12_pg2 &fmc_a13_pg3 &fmc_a14_pg4 &fmc_a15_pg5 &fmc_d0_pd14 &fmc_d1_pd15 &fmc_d2_pd0 &fmc_d3_pd1 &fmc_d4_pe7 &fmc_d5_pe8 &fmc_d6_pe9 &fmc_d7_pe10 &fmc_d8_pe11 &fmc_d9_pe12 &fmc_d10_pe13 &fmc_d11_pe14 &fmc_d12_pe15 &fmc_d13_pd8 &fmc_d14_pd9 &fmc_d15_pd10 >;
			pinctrl-names = "default";
			sdram: sdram {
				compatible = "st,stm32-fmc-sdram";
				#address-cells = < 0x1 >;
				#size-cells = < 0x0 >;
				label = "STM32_FMC_SDRAM";
				status = "okay";
				power-up-delay = < 0x64 >;
				num-auto-refresh = < 0x1 >;
				mode-register = < 0x0 >;
				refresh-rate = < 0x56a >;
				bank@1 {
					reg = < 0x1 >;
					st,sdram-control = < 0x0 0x4 0x10 0x40 0x100 0xc00 0x0 0x2000 >;
					st,sdram-timing = < 0x2 0x7 0x4 0x7 0x2 0x2 0x2 >;
				};
			};
		};
		ltdc: display-controller@40016800 {
			compatible = "st,stm32-ltdc";
			reg = < 0x40016800 0x200 >;
			interrupts = < 0x58 0x0 >, < 0x59 0x0 >;
			interrupt-names = "ltdc", "ltdc_er";
			clocks = < &rcc 0x44 0x4000000 >;
			status = "okay";
			label = "LTDC";
			pinctrl-0 = < &ltdc_r2_pc10 &ltdc_r3_pb0 &ltdc_r4_pa11 &ltdc_r5_pa12 &ltdc_r6_pb1 &ltdc_r7_pg6 &ltdc_g2_pa6 &ltdc_g3_pg10 &ltdc_g4_pb10 &ltdc_g5_pb11 &ltdc_g6_pc7 &ltdc_g7_pd3 &ltdc_b2_pd6 &ltdc_b3_pg11 &ltdc_b4_pg12 &ltdc_b5_pa3 &ltdc_b6_pb8 &ltdc_b7_pb9 &ltdc_de_pf10 &ltdc_clk_pg7 &ltdc_hsync_pc6 &ltdc_vsync_pa4 >;
			pinctrl-names = "default";
			ext-sdram = < &sdram2 >;
			width = < 0xf0 >;
			height = < 0x140 >;
			hsync-pol = < 0x0 >;
			vsync-pol = < 0x0 >;
			de-pol = < 0x0 >;
			pclk-pol = < 0x0 >;
			hsync-duration = < 0xa >;
			vsync-duration = < 0x2 >;
			hbp-duration = < 0x14 >;
			vbp-duration = < 0x2 >;
			hfp-duration = < 0xa >;
			vfp-duration = < 0x4 >;
			def-back-color-red = < 0xff >;
			def-back-color-green = < 0xff >;
			def-back-color-blue = < 0xff >;
		};
	};
	cpus {
		#address-cells = < 0x1 >;
		#size-cells = < 0x0 >;
		cpu@0 {
			device_type = "cpu";
			compatible = "arm,cortex-m4f";
			reg = < 0x0 >;
		};
	};
	sram0: memory@20000000 {
		compatible = "mmio-sram";
		reg = < 0x20000000 0x30000 >;
	};
	clocks {
		clk_hse: clk-hse {
			#clock-cells = < 0x0 >;
			compatible = "st,stm32-hse-clock";
			status = "okay";
			clock-frequency = < 0x7a1200 >;
			phandle = < 0x54 >;
		};
		clk_hsi: clk-hsi {
			#clock-cells = < 0x0 >;
			compatible = "fixed-clock";
			clock-frequency = < 0xf42400 >;
			status = "disabled";
		};
		clk_lse: clk-lse {
			#clock-cells = < 0x0 >;
			compatible = "fixed-clock";
			clock-frequency = < 0x8000 >;
			status = "disabled";
		};
		clk_lsi: clk-lsi {
			#clock-cells = < 0x0 >;
			compatible = "fixed-clock";
			clock-frequency = < 0x7d00 >;
			status = "disabled";
		};
		pll: pll {
			#clock-cells = < 0x0 >;
			compatible = "st,stm32f4-pll-clock";
			status = "okay";
			div-m = < 0x8 >;
			mul-n = < 0x150 >;
			div-p = < 0x2 >;
			div-q = < 0x7 >;
			clocks = < &clk_hse >;
			phandle = < 0x2 >;
		};
	};
	otgfs_phy: otgfs_phy {
		compatible = "usb-nop-xceiv";
		#phy-cells = < 0x0 >;
		label = "OTGFS_PHY";
		phandle = < 0xc >;
	};
	otghs_fs_phy: otghs_fs_phy {
		compatible = "usb-nop-xceiv";
		#phy-cells = < 0x0 >;
		label = "OTGHS_FS_PHY";
		phandle = < 0xe >;
	};
	ccm0: memory@10000000 {
		compatible = "zephyr,memory-region", "st,stm32-ccm";
		reg = < 0x10000000 0x10000 >;
		zephyr,memory-region = "CCM";
	};
	sdram2: sdram@d0000000 {
		compatible = "zephyr,memory-region", "mmio-sram";
		device_type = "memory";
		reg = < 0xd0000000 0x800000 >;
		zephyr,memory-region = "SDRAM2";
		phandle = < 0x53 >;
	};
	leds {
		compatible = "gpio-leds";
		orange_led_3: led_3 {
			gpios = < &gpiog 0xd 0x0 >;
			label = "User LD3";
		};
		green_led_4: led_4 {
			gpios = < &gpiog 0xe 0x0 >;
			label = "User LD4";
		};
		mc_led0: mc_led_0 {
			gpios = < &gpioe 0x0 0x0 >;
			label = "MC1-Board LED0";
		};
		mc_led1: mc_led_1 {
			gpios = < &gpioe 0x1 0x0 >;
			label = "MC1-Board LED1";
		};
		mc_led2: mc_led_2 {
			gpios = < &gpioe 0x2 0x0 >;
			label = "MC1-Board LED2";
		};
		mc_led3: mc_led_3 {
			gpios = < &gpioe 0x3 0x0 >;
			label = "MC1-Board LED3";
		};
	};
	gpio_keys {
		compatible = "gpio-keys";
		user_button: button {
			label = "User";
			gpios = < &gpioa 0x0 0x1 >;
		};
		mc_t0: mc_button_0 {
			gpios = < &gpiog 0x0 0x1 >;
			label = "MC1-Board button T0";
		};
		mc_t1: mc_button_1 {
			gpios = < &gpiog 0x1 0x1 >;
			label = "MC1-Board button T1";
		};
		mc_t2: mc_button_2 {
			gpios = < &gpiog 0x2 0x1 >;
			label = "MC1-Board button T2";
		};
		mc_t3: mc_button_3 {
			gpios = < &gpiog 0x3 0x1 >;
			label = "MC1-Board button T3";
		};
		mc_s0: mc_switch_0 {
			gpios = < &gpiof 0x3 0x1 >;
			label = "MC1-Board switch S0";
		};
		mc_s1: mc_switch_1 {
			gpios = < &gpiof 0x4 0x1 >;
			label = "MC1-Board switch S1";
		};
		mc_s2: mc_switch_2 {
			gpios = < &gpiof 0x5 0x1 >;
			label = "MC1-Board switch S2";
		};
		mc_s3: mc_switch_3 {
			gpios = < &gpiof 0x6 0x1 >;
			label = "MC1-Board switch S3";
		};
	};
};
